# STC32G144K246 register map
Vendor: STC; File version: 2.0
Registers are 8-bit, read-write, no defined reset value unless marked. A register's access mark holds for its fields unless they carry their own. Offsets are from the block's base; [hi:lo] are bit positions.

## PGA4 — 可编程增益放大器 / 运放 4
Base 0x007EF60C
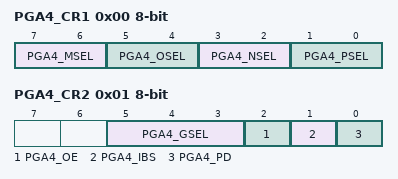
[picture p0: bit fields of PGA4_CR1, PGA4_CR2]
0x00 PGA4_CR1 — 运放4控制寄存器1
  [7:6] PGA4_MSEL — PGA4工作模式选择寄存器
    0=通用运放模式; 1=缓冲模式; 2=反相放大模式; 3=非反相放大模式
  [5:4] PGA4_OSEL — PGA4输出端口选择寄存器
    0=P1.3; 1=P4.0; 2=P7.4; 3=P6.3
  [3:2] PGA4_NSEL — PGA4负极端口选择寄存器
    0=P1.7; 1=P6.5; 2=P3.3; 3=DAC1O
  [1:0] PGA4_PSEL — PGA4正极端口选择寄存器
    0=P1.6; 1=P6.3; 2=P6.4; 3=DAC2O
0x01 PGA4_CR2 — 运放4控制寄存器2
  [5:3] PGA4_GSEL — PGA4增益控制寄存器
    0=反相放大增益倍数：N/A；非反相放大增益倍数：N/A; 1=反相放大增益倍数：1；非反相放大增益倍数：2; 2=反相放大增益倍数：2；非反相放大增益倍数：3; 3=反相放大增益倍数：4；非反相放大增益倍数：5; 4=反相放大增益倍数：8；非反相放大增益倍数：9; 5=反相放大增益倍数：16；非反相放大增益倍数：17; 6=反相放大增益倍数：32；非反相放大增益倍数：33; 7=反相放大增益倍数：48；非反相放大增益倍数：49
  [2] PGA4_OE — PGA4 输出控制位
    0=禁止PGA4 输出; 1=允许PGA4 输出
  [1] PGA4_IBS — PGA4 偏压电流大小选择
    0=正常电流大小; 1=电流倍增
  [0] PGA4_PD — PGA4 电源控制
    0=禁止掉电（使能PGA4）; 1=使能掉电（关闭PGA4）

## DAC1 — DAC1 控制、分频和状态
Base 0x007EF610
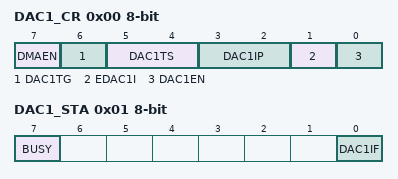
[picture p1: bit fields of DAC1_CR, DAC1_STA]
0x00 DAC1_CR ro — DAC1控制寄存器
  [7] DMAEN — DMA模式控制位
    0=禁止DMA 模式; 1=使能DMA 模式
  [6] DAC1TG — 触发DAC输出
    0=无效; 1=触发DAC 输出，硬件自动清零
  [5:4] DAC1TS — DAC1触发源选择
    0=自动触发源：单次触发；触发说明：软件使用DAC1TG触发; 1=自动触发源：定时器17自动触发；触发说明：; 2=自动触发源：定时器18自动触发；触发说明：; 3=自动触发源：连续触发模式；触发说明：
  [3:2] DAC1IP — DAC1中断优先级控制位
    0=DAC1 中断优先级为0 级（最低级）; 1=DAC1 中断优先级为1 级（较低级）; 2=DAC1 中断优先级为2 级（较高级）; 3=DAC1 中断优先级为3 级（最高级）
  [1] EDAC1I — DAC1中断控制位
    0=禁止DAC1 中断; 1=使能DAC1 中断
  [0] DAC1EN — DAC1模块使能控制位
    0=禁止DAC1 功能; 1=使能DAC1 功能
0x01 DAC1_STA ro — DAC1状态寄存器
  [7] BUSY — DAC1模块忙标准位（只读）
  [0] DAC1IF — DAC1中断请求标志位，需要软件写0清零
0x04 DAC1_DIVH — DAC1时钟分频寄存器
  [1:0] DAC1_DIV — DAC1 时钟分频。 DAC1 模块的工作频率=系统时钟 / 4 / DAC1_DIV[9:0]，当DAC1_DIV[9:0]的值为0 时，DAC1 直接使用 系统时钟。 必须保证DAC1 模块的工作频率不得高于2MHz
0x05 DAC1_DIVL — DAC1时钟分频寄存器
  [7:0] DAC1_DIV — DAC1 时钟分频。 DAC1 模块的工作频率=系统时钟 / 4 / DAC1_DIV[9:0]，当DAC1_DIV[9:0]的值为0 时，DAC1 直接使用 系统时钟。 必须保证DAC1 模块的工作频率不得高于2MHz

## DAC2 — DAC2 控制、分频和状态
Base 0x007EF628
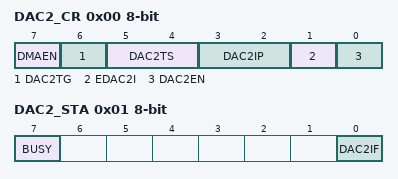
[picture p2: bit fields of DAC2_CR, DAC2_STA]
0x00 DAC2_CR ro — DAC2控制寄存器
  [7] DMAEN — DMA模式控制位
    0=禁止DMA 模式; 1=使能DMA 模式
  [6] DAC2TG — 触发DAC输出
    0=无效; 1=触发DAC 输出，硬件自动清零
  [5:4] DAC2TS — DAC2触发源选择
    0=自动触发源：单次触发；触发说明：软件使用DAC2TG触发; 1=自动触发源：定时器17自动触发；触发说明：; 2=自动触发源：定时器18自动触发；触发说明：; 3=自动触发源：连续触发模式；触发说明：
  [3:2] DAC2IP — DAC2中断优先级控制位
    0=DAC2 中断优先级为0 级（最低级）; 1=DAC2 中断优先级为1 级（较低级）; 2=DAC2 中断优先级为2 级（较高级）; 3=DAC2 中断优先级为3 级（最高级）
  [1] EDAC2I — DAC2中断控制位
    0=禁止DAC2 中断; 1=使能DAC2 中断
  [0] DAC2EN — DAC2模块使能控制位
    0=禁止DAC2 功能; 1=使能DAC2 功能
0x01 DAC2_STA ro — DAC2状态寄存器
  [7] BUSY — DAC2模块忙标准位（只读）
  [0] DAC2IF — DAC2中断请求标志位，需要软件写0清零
0x04 DAC2_DIVH — DAC2时钟分频寄存器
  [1:0] DAC2_DIV — DAC2 时钟分频。 DAC2 模块的工作频率=系统时钟 / 4 / DAC2_DIV[9:0]，当DAC2_DIV[9:0]的值为0 时，DAC2 直接使用 系统时钟。 必须保证DAC2 模块的工作频率不得高于2MHz
0x05 DAC2_DIVL — DAC2时钟分频寄存器
  [7:0] DAC2_DIV — DAC2 时钟分频。 DAC2 模块的工作频率=系统时钟 / 4 / DAC2_DIV[9:0]，当DAC2_DIV[9:0]的值为0 时，DAC2 直接使用 系统时钟。 必须保证DAC2 模块的工作频率不得高于2MHz

## IAP — IAP / EEPROM 控制与时序；不暴露触发和缓冲区
Base 0x100000C3
0x00 IAP_ADDRH ro — IAP高地址寄存器
  [7:0] IAP_ADDR — 尚未自动匹配到此字段的独立说明；请查看下方章节说明。
0x01 IAP_ADDRL ro — IAP低地址寄存器
  [7:0] IAP_ADDR — 尚未自动匹配到此字段的独立说明；请查看下方章节说明。
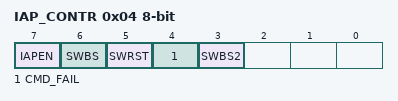
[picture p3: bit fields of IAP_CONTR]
0x04 IAP_CONTR ro — IAP控制寄存器
  [7] IAPEN — EEPROM操作使能控制位
    0=禁止EEPROM 操作; 1=使能EEPROM 操作
  [6] SWBS — 尚未自动匹配到此字段的独立说明；请查看下方章节说明。
  [5] SWRST — 软件复位触发位
    0=对单片机无影响; 1=触发软件复位
  [4] CMD_FAIL — EEPROM操作失败状态位，需要软件清零
    0=EEPROM 操作正确; 1=EEPROM 操作失败
  [3] SWBS2 — 尚未自动匹配到此字段的独立说明；请查看下方章节说明。
0x32 IAP_TPS ro — IAP等待时间控制寄存器
  [7:0] IAP_TPS — 尚未自动匹配到此字段的独立说明；请查看下方章节说明。
0x33 IAP_ADDRE ro — IAP扩展高地址寄存器
  [7:0] IAP_ADDR — 尚未自动匹配到此字段的独立说明；请查看下方章节说明。

## SPI1 — SPI1 接口
Base 0x007EFE90
0x00 SPI_CLKDIV — SPI时钟预分配寄存器
  [7:0] SPI_CLKDIV — 高速SPI 时钟分频系数。
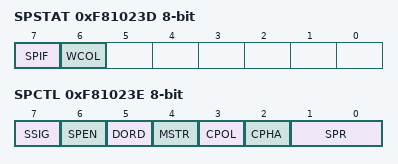
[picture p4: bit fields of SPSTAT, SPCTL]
0xF81023D SPSTAT ro — SPI状态寄存器
  [7] SPIF — SPI 数据传输完成中断请求标志。需要软件写“1”清零。
  [6] WCOL — SPI 写冲突标志位。 当SPI 在进行数据传输的过程中写SPDAT 寄存器时，硬件将此位置1。 注意：此标志位必须用户通过软件方式向此位写1 进行清零。
0xF81023E SPCTL — SPI控制寄存器
  [7] SSIG — SS 引脚功能控制位
    0=SS 引脚确定器件是主机还是从机; 1=忽略SS 引脚功能，使用MSTR 确定器件是主机还是从机
  [6] SPEN — SPI 使能控制位
    0=关闭SPI 功能; 1=使能SPI 功能
  [5] DORD — SPI 数据位发送/接收的顺序
    0=先发送/接收数据的高位（MSB）; 1=先发送/接收数据的低位（LSB）
  [4] MSTR — 器件主/从模式选择位 设置主机模式： 若SSIG＝0，则SS 管脚必须为高电平且设置MSTR 为1 若SSIG＝1，则只需要设置MSTR 为1（忽略SS 管脚的电平） 设置从机模式： 若SSIG＝0，则SS 管脚必须为低电平（与MSTR 位无关） 若SSIG＝1，则只需要设置MSTR 为0（忽略SS
  [3] CPOL — SPI 时钟极性控制
    0=SCLK 空闲时为低电平，SCLK 的前时钟沿为上升沿，后时钟沿为下降沿; 1=SCLK 空闲时为高电平，SCLK 的前时钟沿为下降沿，后时钟沿为上升沿
  [2] CPHA — SPI 时钟相位控制
    0=数据SS 管脚为低电平驱动第一位数据并在SCLK 的后时钟沿改变数据，前时钟沿采样数据（必; 1=数据在SCLK 的前时钟沿驱动，后时钟沿采样
  [1:0] SPR — SPI 时钟频率选择
    0=SPI 输入时钟/4; 1=SPI 输入时钟/8; 2=SPI 输入时钟/16; 3=SPI 输入时钟/2
